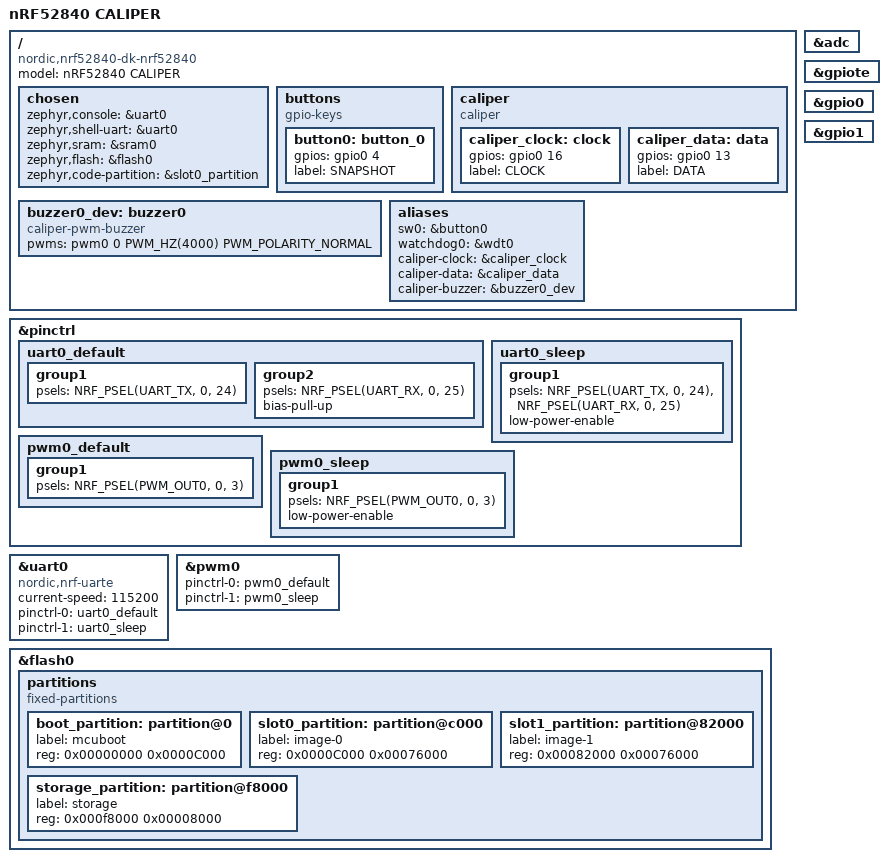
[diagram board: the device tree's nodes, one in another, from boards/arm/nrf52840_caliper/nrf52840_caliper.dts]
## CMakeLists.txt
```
# SPDX-License-Identifier: Apache-2.0

cmake_minimum_required(VERSION 3.20.0)

set_property(GLOBAL APPEND PROPERTY HEX_FILES_TO_MERGE
      ${app_provision_hex})

set(BOARD_ROOT ${CMAKE_CURRENT_SOURCE_DIR})
set(DTS_ROOT_BINDINGS "${CMAKE_CURRENT_SOURCE_DIR}")

# Select the board on the command line, e.g.:
#   west build -b xiao_caliper/nrf52840
# (a BOARD set here would override -b and defeat board qualifiers)

find_package(Zephyr REQUIRED HINTS $ENV{ZEPHYR_BASE})
project(caliper)

include_directories(app PRIVATE inc)

FILE(GLOB app_sources src/*.c)
target_sources(app PRIVATE
  ${app_sources}
  )

# zephyr_compile_options(-save-temps)
```

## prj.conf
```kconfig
#------------------------------------------------
CONFIG_DEBUG=y
CONFIG_GPIO=y
CONFIG_HEAP_MEM_POOL_SIZE=6144
CONFIG_SYSTEM_WORKQUEUE_STACK_SIZE=2048
CONFIG_BUILD_OUTPUT_HEX=y
CONFIG_CBPRINTF_FP_SUPPORT=y
CONFIG_HWINFO=y
CONFIG_HWINFO_NRF=y
CONFIG_REBOOT=y
CONFIG_PWM=y

#
# Why is is option necessary?
#  "No SOURCES given to Zephyr library: xxxxxx"
#
CONFIG_RESET=n

#------------------------------------------------

CONFIG_BT=y
CONFIG_BT_MAX_CONN=2
CONFIG_BT_MAX_PAIRED=2
CONFIG_BT_SMP=y
CONFIG_BT_PERIPHERAL=y
CONFIG_BT_PERIPHERAL_PREF_TIMEOUT=2000
CONFIG_BT_DEVICE_NAME="Caliper Keyboard"
CONFIG_BT_DEVICE_APPEARANCE=961

CONFIG_BT_KEYS_OVERWRITE_OLDEST=y
CONFIG_BT_SMP_ALLOW_UNAUTH_OVERWRITE=y
CONFIG_BT_SMP_SC_PAIR_ONLY=y

CONFIG_BT_SETTINGS=n
CONFIG_BT_LOG_LEVEL_WRN=y

#
# The FIXED_PASSKEY option will generate a warning: ignore it.
# HOG_Keyboard has no method to display a central-side passkey, 
# so HOG_Keyboard uses a FIXED_PASSKEY thereby forcing the 
# central-side into using our fixed passkey.
#
#CONFIG_BT_FIXED_PASSKEY=y

CONFIG_BT_L2CAP_TX_BUF_COUNT=10
CONFIG_BT_BUF_ACL_TX_COUNT=10
CONFIG_BT_BUF_EVT_RX_COUNT=14

#CONFIG_BT_USE_DEBUG_KEYS=y
#CONFIG_BT_STORE_DEBUG_KEYS=y
#CONFIG_BT_LOG_SNIFFER_INFO=y
#CONFIG_BT_SMP_LOG_LEVEL_DBG=y

#------------------------------------------------

CONFIG_ADC_INIT_PRIORITY=50
CONFIG_ADC=y
CONFIG_ADC_ASYNC=y
CONFIG_ADC_LOG_LEVEL_DEFAULT=y
CONFIG_ADC_NRFX_SAADC=y
CONFIG_ADC_SHELL=y

CONFIG_BT_BAS=y

#------------------------------------------------

CONFIG_BT_DIS=y
CONFIG_BT_DIS_PNP=y
CONFIG_BT_DIS_MANUF_NAME_STR="Manufacturer"
CONFIG_BT_DIS_PNP_VID_SRC=2
CONFIG_BT_DIS_PNP_VID=0x1915
CONFIG_BT_DIS_PNP_PID=0xEEEF
CONFIG_BT_DIS_PNP_VER=0x0100

#------------------------------------------------

CONFIG_FLASH=y
CONFIG_FLASH_PAGE_LAYOUT=y
CONFIG_FLASH_MAP=y
CONFIG_NVS=y
CONFIG_SETTINGS=y
CONFIG_MPU_ALLOW_FLASH_WRITE=y

#------------------------------------------------

CONFIG_UART_INTERRUPT_DRIVEN=y
CONFIG_CLOCK_CONTROL_NRF_SHELL=n

CONFIG_FLASH_SHELL=y
CONFIG_FLASH_SHELL_BUFFER_SIZE=0x1000
CONFIG_RING_BUFFER=y

CONFIG_HWINFO_SHELL=y
CONFIG_GETOPT=y
CONFIG_POSIX_C_LIB_EXT=y

CONFIG_SHELL_LOG_LEVEL_WRN=y
CONFIG_SHELL_BACKEND_SERIAL_LOG_LEVEL_WRN=y

CONFIG_SHELL=y
CONFIG_SHELL_BACKENDS=y
CONFIG_SHELL_BACKEND_SERIAL=y
CONFIG_SHELL_BACKEND_SERIAL_INIT_PRIORITY=0
CONFIG_SHELL_PROMPT_UART="uart:~$ "
CONFIG_SHELL_BACKEND_SERIAL_INTERRUPT_DRIVEN=y
CONFIG_SHELL_BACKEND_SERIAL_TX_RING_BUFFER_SIZE=8
CONFIG_SHELL_BACKEND_SERIAL_RX_RING_BUFFER_SIZE=64
CONFIG_SHELL_BACKEND_SERIAL_LOG_MESSAGE_QUEUE_TIMEOUT=100
CONFIG_SHELL_BACKEND_SERIAL_LOG_MESSAGE_QUEUE_SIZE=512
CONFIG_SHELL_STACK_SIZE=2048
CONFIG_SHELL_BACKSPACE_MODE_DELETE=y
CONFIG_SHELL_CMD_BUFF_SIZE=256
CONFIG_SHELL_PRINTF_BUFF_SIZE=30
CONFIG_SHELL_DEFAULT_TERMINAL_WIDTH=80
CONFIG_SHELL_DEFAULT_TERMINAL_HEIGHT=24
CONFIG_SHELL_ARGC_MAX=20
CONFIG_SHELL_TAB=y
CONFIG_SHELL_TAB_AUTOCOMPLETION=y
CONFIG_SHELL_WILDCARD=y
CONFIG_SHELL_ECHO_STATUS=y
CONFIG_SHELL_VT100_COMMANDS=y
CONFIG_SHELL_METAKEYS=y
CONFIG_SHELL_HELP=y
CONFIG_SHELL_HELP_OPT_PARSE=y
CONFIG_SHELL_HELP_ON_WRONG_ARGUMENT_COUNT=y
CONFIG_SHELL_HISTORY=y
CONFIG_SHELL_HISTORY_BUFFER=512
CONFIG_SHELL_STATS=y
CONFIG_SHELL_CMDS=y
CONFIG_SHELL_CMDS_RESIZE=y
CONFIG_SHELL_AUTOSTART=y
CONFIG_SHELL_CMDS_RETURN_VALUE=y
CONFIG_KERNEL_SHELL=y
CONFIG_DEVICE_SHELL=y
CONFIG_DEVMEM_SHELL=y

CONFIG_SHELL_LOG_FORMAT_TIMESTAMP=n
CONFIG_SHELL_LOG_BACKEND=n

#------------------------------------------------

CONFIG_GPIO=y

#------------------------------------------------

CONFIG_WATCHDOG=y
CONFIG_WDT_LOG_LEVEL_DBG=y

#------------------------------------------------

CONFIG_USE_SEGGER_RTT=y
CONFIG_SEGGER_RTT_MAX_NUM_UP_BUFFERS=5
CONFIG_SEGGER_RTT_MAX_NUM_DOWN_BUFFERS=5
CONFIG_SEGGER_RTT_BUFFER_SIZE_UP=2048
CONFIG_SEGGER_RTT_BUFFER_SIZE_DOWN=16
CONFIG_SEGGER_RTT_PRINTF_BUFFER_SIZE=64
CONFIG_SEGGER_RTT_MODE_NO_BLOCK_SKIP=y

CONFIG_LOG=y
CONFIG_LOG_DEFAULT_LEVEL=3
CONFIG_LOG_OVERRIDE_LEVEL=0
CONFIG_LOG_MAX_LEVEL=4
CONFIG_LOG_FUNC_NAME_PREFIX_DBG=y
CONFIG_LOG_PRINTK=y
CONFIG_LOG_MODE_OVERFLOW=y
CONFIG_LOG_PROCESS_TRIGGER_THRESHOLD=30
CONFIG_LOG_PROCESS_THREAD=y
CONFIG_LOG_PROCESS_THREAD_SLEEP_MS=1000
CONFIG_LOG_PROCESS_THREAD_STACK_SIZE=768
CONFIG_LOG_BUFFER_SIZE=2048

CONFIG_LOG_BACKEND_RTT=y
CONFIG_LOG_BACKEND_RTT_MODE_DROP=y
CONFIG_LOG_BACKEND_RTT_BUFFER=0
CONFIG_LOG_BACKEND_SHOW_COLOR=y
CONFIG_LOG_BACKEND_RTT_MESSAGE_SIZE=128

CONFIG_LOG_BACKEND_UART=n
CONFIG_LOG_BACKEND_FORMAT_TIMESTAMP=n
CONFIG_LOG_BACKEND_SHOW_COLOR=n
```

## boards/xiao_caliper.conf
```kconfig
# xiao_caliper: console/shell on the UART header (see xiao_caliper.overlay).

# Do not bring up the USB stack / CDC ACM console the board enables by default.
CONFIG_BOARD_SERIAL_BACKEND_CDC_ACM=n
CONFIG_SERIAL=y
CONFIG_CONSOLE=y
CONFIG_UART_CONSOLE=y

# LOG_INF output: prj.conf only enables the RTT backend, and the shell log
# backend is off.  Send logs through the shell on the UART, at INF level.
# (Do not also enable LOG_BACKEND_UART: it would fight the shell for uart0.)
CONFIG_SHELL_LOG_BACKEND=y
CONFIG_SHELL_BACKEND_SERIAL_LOG_LEVEL_INF=y
```

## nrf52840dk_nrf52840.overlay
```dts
/* 
 *  Copyright (c) 2023 Callender-Consulting
 *
 *  SPDX-License-Identifier: Apache-2.0
 */

#include <zephyr/dt-bindings/pwm/pwm.h>

/*
 *  Add Caliper GPIO pins to DTS config
 */

/ {
    chosen {
        zephyr,console = &uart0;
        zephyr,shell-uart = &uart0;
        zephyr,sram = &sram0;
        zephyr,flash = &flash0;
        zephyr,code-partition = &slot0_partition;
    };

    caliper {
        caliper_data: data {
            gpios = <&gpio0 3 0>;
            label = "DATA";
        };
        compatible = "caliper";
        caliper_clock: clock {
            gpios = <&gpio0 4 0>;
            label = "CLOCK";
        };
    };

    /*
     * CMT-322-65-SMT-TR passive piezo buzzer, driven via PWM on P0.28
     * (see pwm0_default below).  The period cell is a documentary default;
     * the application selects the actual tone frequency at runtime.
     */
    buzzer0_dev: buzzer0 {
        compatible = "caliper-pwm-buzzer";
        pwms = <&pwm0 0 PWM_HZ(4000) PWM_POLARITY_NORMAL>;
    };

    aliases {
        watchdog0 = &wdt0;
        caliper-data   = &caliper_data;
        caliper-clock  = &caliper_clock;
        caliper-buzzer = &buzzer0_dev;
    };
};

&pinctrl {
    uart0_default: uart0_default {
        group1 {
            psels = <NRF_PSEL(UART_TX,  0, 24)>;
        };
        group2 {
            psels = <NRF_PSEL(UART_RX,  0, 25)>;
            bias-pull-up;
        };
    };

    uart0_sleep: uart0_sleep {
        group1 {
            psels = <NRF_PSEL(UART_TX, 0, 24)>,
                    <NRF_PSEL(UART_RX, 0, 25)>;
            low-power-enable;
        };
    };

    pwm0_default: pwm0_default {
        group1 {
            psels = <NRF_PSEL(PWM_OUT0, 0, 28)>;
        };
    };

    pwm0_sleep: pwm0_sleep {
        group1 {
            psels = <NRF_PSEL(PWM_OUT0, 0, 28)>;
            low-power-enable;
        };
    };    
};

&uart0 {
    compatible = "nordic,nrf-uarte";
    status = "okay";
    current-speed = <115200>;
    pinctrl-0 = <&uart0_default>;
    pinctrl-1 = <&uart0_sleep>;
    pinctrl-names = "default", "sleep";
};
```

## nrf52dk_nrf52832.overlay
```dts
/* 
 *  Copyright (c) 2023 Callender-Consulting
 *
 *  SPDX-License-Identifier: Apache-2.0
 */

/*
 *  Add Caliper GPIO pins to DTS config
 */

/ {
    caliper {
        compatible = "caliper";
        caliper_clock: clock {
            gpios = <&gpio0 3 0>;
            label = "CLOCK";
        };
        caliper_data: data {
            gpios = <&gpio0 4 0>;
            label = "DATA";
        };
        caliper_test: test {
            gpios = <&gpio0 28 0>;
            label = "TEST";
        };
    };

    aliases {
        caliper-clock = &caliper_clock;
        caliper-data  = &caliper_data;
        caliper-test  = &caliper_test;
    };
};

#if 0
/delete-node/ &boot_partition;
/delete-node/ &slot0_partition;
/delete-node/ &slot1_partition;
/delete-node/ &scratch_partition;
/delete-node/ &storage_partition;

&flash0 {
    partitions {
        compatible = "fixed-partitions";
        #address-cells = <1>;
        #size-cells = <1>;

        slot0_partition: partition@c000 {
            label = "image-0";
            reg = <0x00000000 0x32000>;
        };
        slot1_partition: partition@3e000 {
            label = "image-1";
            reg = <0x0003E000 0x32000>;
        };
        scratch_partition: partition@70000 {
            label = "image-scratch";
            reg = <0x00070000 0xa000>;
        };
        storage_partition: partition@7a000 {
            label = "storage";
            reg = <0x0007a000 0x00006000>;
        };
    };
};
#endif
```

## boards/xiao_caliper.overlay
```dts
/*
 * xiao_caliper: put the console and shell on uart0 (115200 8N1) instead of
 * the board default (USB CDC ACM).  uart0 is routed to the J1 header:
 *   USART_TX = P1.11 (XIAO D6)   USART_RX = P1.12 (XIAO D7)
 *
 * Pair with boards/xiao_caliper.conf (turns the USB CDC backend off).
 * Delete both files to return to the USB console.
 */
/ {
	chosen {
		zephyr,console = &uart0;
		zephyr,shell-uart = &uart0;
	};
};
```

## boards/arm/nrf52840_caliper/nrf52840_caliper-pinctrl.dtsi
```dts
/*
 * Copyright (c) 2023 Callender Consulting
 * SPDX-License-Identifier: Apache-2.0
 */

&pinctrl {
    uart0_default: uart0_default {
        group1 {
            psels = <NRF_PSEL(UART_TX,  0, 24)>;
            psels = <NRF_PSEL(UART_RX,  0, 25)>;
        };
    };

    uart0_sleep: uart0_sleep {
        group1 {
            psels = <NRF_PSEL(UART_TX, 0, 24)>,
                    <NRF_PSEL(UART_RX, 0, 25)>;
            low-power-enable;
        };
    };   
};
```

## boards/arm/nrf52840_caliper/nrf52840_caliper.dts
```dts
/*
 * Copyright (c) 2023 Callender Consulting
 *
 * SPDX-License-Identifier: Apache-2.0
 */

/dts-v1/;
#include <nordic/nrf52840_qiaa.dtsi>
#include <zephyr/dt-bindings/pwm/pwm.h>

/ {
    model = "nRF52840 CALIPER";
    compatible = "nordic,nrf52840-dk-nrf52840";

    chosen {
        zephyr,console = &uart0;
        zephyr,shell-uart = &uart0;
        zephyr,sram = &sram0;
        zephyr,flash = &flash0;
        zephyr,code-partition = &slot0_partition;
    };

    buttons {
        compatible = "gpio-keys";
        button0: button_0 {
            gpios = <&gpio0 4 (GPIO_PULL_DOWN | GPIO_ACTIVE_HIGH)>;
            label = "SNAPSHOT";
        };
    };

    caliper {
        compatible = "caliper";
        caliper_clock: clock {
            gpios = <&gpio0 16 0>;
            label = "CLOCK";
        };
        caliper_data: data {
            gpios = <&gpio0 13 0>;
            label = "DATA";
        };
    };

    /*
     * CMT-322-65-SMT-TR passive piezo buzzer, driven via PWM on P0.03.
     * Bound to this application's "caliper-pwm-buzzer" binding.
     * The period cell below (PWM_HZ(4000)) is a documentary default; the
     * application selects the actual tone frequency at runtime.
     */
    buzzer0_dev: buzzer0 {
        compatible = "caliper-pwm-buzzer";
        pwms = <&pwm0 0 PWM_HZ(4000) PWM_POLARITY_NORMAL>;
    };

    aliases {
        sw0            = &button0;
        watchdog0      = &wdt0;
        caliper-clock  = &caliper_clock;
        caliper-data   = &caliper_data;
        caliper-buzzer = &buzzer0_dev;
    };
};

&adc {
    status = "okay";
};

&gpiote {
    status = "okay";
};

&gpio0 {
    status = "okay";
};

&gpio1 {
    status = "okay";
};

&pinctrl {
    uart0_default: uart0_default {
        group1 {
            psels = <NRF_PSEL(UART_TX,  0, 24)>;
        };
        group2 {
            psels = <NRF_PSEL(UART_RX,  0, 25)>;
            bias-pull-up;
        };
    };

    uart0_sleep: uart0_sleep {
        group1 {
            psels = <NRF_PSEL(UART_TX, 0, 24)>,
                    <NRF_PSEL(UART_RX, 0, 25)>;
            low-power-enable;
        };
    };

    pwm0_default: pwm0_default {
        group1 {
            psels = <NRF_PSEL(PWM_OUT0, 0, 3)>;
        };
    };

    pwm0_sleep: pwm0_sleep {
        group1 {
            psels = <NRF_PSEL(PWM_OUT0, 0, 3)>;
            low-power-enable;
        };
    };
};

&uart0 {
    compatible = "nordic,nrf-uarte";
    status = "okay";
    current-speed = <115200>;
    pinctrl-0 = <&uart0_default>;
    pinctrl-1 = <&uart0_sleep>;
    pinctrl-names = "default", "sleep";
};

&pwm0 {
    status = "okay";
    pinctrl-0 = <&pwm0_default>;
    pinctrl-1 = <&pwm0_sleep>;
    pinctrl-names = "default", "sleep";
};

&flash0 {

    partitions {
        compatible = "fixed-partitions";
        #address-cells = <1>;
        #size-cells = <1>;

        boot_partition: partition@0 {
            label = "mcuboot";
            reg = <0x00000000 0x0000C000>;
        };
        slot0_partition: partition@c000 {
            label = "image-0";
            reg = <0x0000C000 0x00076000>;
        };
        slot1_partition: partition@82000 {
            label = "image-1";
            reg = <0x00082000 0x00076000>;
        };

        /*
         * The flash starting at 0x000f8000 and ending at
         * 0x000fffff is reserved for use by the application.
         */

        /*
         * Storage partition will be used by FCB/LittleFS/NVS
         * if enabled.
         */
        storage_partition: partition@f8000 {
            label = "storage";
            reg = <0x000f8000 0x00008000>;
        };
    };
};

#if 0
zephyr_udc0: &usbd {
    compatible = "nordic,nrf-usbd";
    status = "okay";
};
#endif
```

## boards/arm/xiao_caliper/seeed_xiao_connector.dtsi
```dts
/*
 * Copyright (c) 2022 Peter Johanson
 * Copyright (c) 2022 Marcin Niestroj
 * Copyright (c) 2026 Robin Callender
 *
 * SPDX-License-Identifier: Apache-2.0
 */

/ {
	xiao_d: connector {
		compatible = "seeed,xiao-gpio";
		#gpio-cells = <2>;
		gpio-map-mask = <0xffffffff 0xffffffc0>;
		gpio-map-pass-thru = <0 0x3f>;
		gpio-map = <0 0 &gpio0 2 0>,		/* D0 */
			   <1 0 &gpio0 3 0>,		/* D1 */
			   <2 0 &gpio0 28 0>,		/* D2 */
			   <3 0 &gpio0 29 0>,		/* D3 */
			   <4 0 &gpio0 4 0>,		/* D4 */
			   <5 0 &gpio0 5 0>,		/* D5 */
			   <6 0 &gpio1 11 0>,		/* D6 */
			   <7 0 &gpio1 12 0>,		/* D7 */
			   <8 0 &gpio1 13 0>,		/* D8 */
			   <9 0 &gpio1 14 0>,		/* D9 */
			   <10 0 &gpio1 15 0>;		/* D10 */
	};
};

xiao_spi: &spi2 {};

xiao_i2c: &i2c1 {};

xiao_serial: &uart0 {};

xiao_adc: &adc {};
```

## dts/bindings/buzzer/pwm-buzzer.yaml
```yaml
# Copyright (c) 2023  Callender_Consulting
# SPDX-License-Identifier: Apache-2.0

description: PWM Buzzer parent node

compatible: "pwm-buzzer"

child-binding:
  description: PWM Buzzer child node
  properties:
    pwms:
      required: true
      type: phandle-array

    label:
      type: string
      description: |
        Human readable string describing the Buzzer. 
```

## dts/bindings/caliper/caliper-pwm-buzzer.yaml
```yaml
# Copyright (c) 2026 Callender-Consulting
# SPDX-License-Identifier: Apache-2.0

description: |
  Passive piezo buzzer driven by one PWM channel (e.g. through a FET).
  The application chooses tone frequency and duty cycle at run time; the
  period cell in 'pwms' is only a documentary default.

compatible: "caliper-pwm-buzzer"

include: base.yaml

properties:
  pwms:
    type: phandle-array
    required: true
```

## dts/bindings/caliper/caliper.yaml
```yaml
description: Digital Caliper

compatible: "caliper"

child-binding:
    description: caliper child node
    properties:
        gpios:
            type: phandle-array
            required: true
        label:
            required: true
            type: string
        debounce:
            required: false
            type: int
```

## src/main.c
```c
/* 
 *  main.c - Application main entry point 
 */
#include <stdio.h>
#include <stdlib.h>
#include <zephyr/kernel.h>
#include <zephyr/sys/printk.h>
#include <zephyr/drivers/hwinfo.h> 

#include "events.h"
#include "watchdog.h"
#include "shell.h"
#include "battery.h"
#include "app_uicr.h"
#include "ble_base.h"
#include "ble_alt.h"
#include "framer.h"
#include "buzzer.h"

#include <zephyr/logging/log.h>
LOG_MODULE_REGISTER(main, 3);

#define STACKSIZE 1024
#define PRIORITY 7

/*---------------------------------------------------------------------------*/
/*                                                                           */
/*---------------------------------------------------------------------------*/

typedef struct {
    uint32_t code;
    char *   text;
} reason_t; 

static reason_t reasons[] = {
    { RESET_PIN,            "Reset Pin"     },  // BIT(0)
    { RESET_SOFTWARE,       "Software"      },  // BIT(1)
    { RESET_BROWNOUT,       "Brown Out"     },  // BIT(2)
    { RESET_POR,            "POR"           },  // BIT(3)
    { RESET_WATCHDOG,       "Watchdog"      },  // BIT(4)
    { RESET_DEBUG,          "Debug"         },  // BIT(5)
    { RESET_SECURITY,       "Security"      },  // BIT(6)
    { RESET_LOW_POWER_WAKE, "Low Pwr Wake"  },  // BIT(7)
    { RESET_CPU_LOCKUP,     "CPU Lockup"    },  // BIT(8)
    { RESET_PARITY,         "Parity"        },  // BIT(9)
    { RESET_PLL,            "PLL"           },  // BIT(10)
    { RESET_CLOCK,          "Clock"         },  // BIT(11)
    { RESET_HARDWARE,       "Hardware"      },  // BIT(12)
    { RESET_USER,           "User"          },  // BIT(13)
    { RESET_TEMPERATURE,    "Temperature"   },  // BIT(14)
};
#define REASONS_COUNT (sizeof(reasons)/sizeof(reason_t))

static bool alt_ble_app = false;

/*---------------------------------------------------------------------------*/
/*                                                                           */
/*---------------------------------------------------------------------------*/
static char * get_reason_text(uint32_t reset_reason)
{
    static char string[48];

    string[0] = 0;

    for(int i=0; i < REASONS_COUNT; i++) {
        if (reset_reason & reasons[i].code) {
            reset_reason &= ~reasons[i].code;
            strcat(string, reasons[i].text);
            if (reset_reason)
                strcat(string, ", ");
        }
    }
    return (char*) &string;
}

/*---------------------------------------------------------------------------*/
/*                                                                           */
/*---------------------------------------------------------------------------*/
bool is_alt_running(void)
{
    return alt_ble_app;
}

/*---------------------------------------------------------------------------*/
/*                                                                           */
/*---------------------------------------------------------------------------*/
void main_thread(void * id, void * unused1, void * unused2)
{
    uint32_t reset_reason = 0;

    hwinfo_get_reset_cause(&reset_reason);
    hwinfo_clear_reset_cause();

    LOG_INF("*** Reset Reason: (0x%02X) %s", 
            reset_reason, get_reason_text(reset_reason));

    app_uicr_init();

    buttons_init();

    if (boot_button_state() == BOOT_OPTIONS_ALTERNATE) {
        LOG_INF("Alternate BLE service starting...");
        alt_ble_app = true;

        ble_alt_init();
    }
    else {
        LOG_INF("Primary BLE service starting...");        
        ble_base_init();
    }

    battery_init();

    framer_init();

    buzzer_init();

    caliper_init();

    events_init();

    caliper_shell_init();

    watchdog_init();   /* watchdog_init never returns */
}


K_THREAD_DEFINE(main_id, STACKSIZE, main_thread,
                NULL, NULL, NULL, PRIORITY, 0, 0);
```

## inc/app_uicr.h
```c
/*
 *   app_uicr.h
 *
 * Copyright (c) 2023, Callender-Consulting LLC
 *
 * SPDX-License-Identifier: Apache-2.0
 */ 
#ifndef __APP_UICR_H
#define __APP_UICR_H

/*---------------------------------------------------------------------------*/
/*                                                                           */
/*---------------------------------------------------------------------------*/

typedef enum{
    INVALID_LINE_END = 0,
    ASCIIZ           = 1,  // ASCII string with zero end
    NEWLINE          = 2,  // ASCII string with \n and zero end
//    HTAB             = 3,  // ASCII Horizontal Tab and zero end
//    VTAB             = 4,  // ASCII Vertical TAB and zero end
} line_end_t;

typedef enum{
    INVALID_STANDARD = 0,
    INCLUDE          = 1,  // include standard unit: mm or inch literal
    EXCLUDE          = 2,  // no standard unit literal
} standard_t;

/*---------------------------------------------------------------------------*/
/*                                                                           */
/*---------------------------------------------------------------------------*/
void       app_uicr_init(void);
line_end_t app_uicr_get_line_end(void);
void       app_uicr_set_line_end(line_end_t line_end);
standard_t app_uicr_get_standard(void);
void       app_uicr_set_standard(standard_t standard);

#endif  /* __APP_UICR_H */
```

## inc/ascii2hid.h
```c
/*
 *  ascii2hid.h
 *
 *  Copyright (c) 2023   Callender-Consulting
 *
 *  SPDX-License-Identifier: Apache-2.0
 */
#ifndef ASCII2HID_H
#define ASCII2HID_H

#include <stdint.h>
#include <stdbool.h>

/*---------------------------------------------------------------------------*/
/*                                                                           */
/*---------------------------------------------------------------------------*/

int ascii_to_hid(uint8_t ascii);
bool needs_shift(uint8_t ascii);

#endif /* ASCII2HID_H */
```

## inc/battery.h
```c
/*
 *   battery.h
 */
#ifndef __BATTERY_H
#define __BATTERY_H

/* Set invalid (uninitialized) percentage value to something very low */
#define BATTERY_LEVEL_INVALID ((uint8_t)5)

/*---------------------------------------------------------------------------*/
/*                                                                           */
/*---------------------------------------------------------------------------*/
int  battery_init(void);
void battery_start(void);
void battery_stop(void);
void battery_ble_events(bool connected);

#endif  /* __BATTERY_H */
```

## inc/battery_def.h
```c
/*
 * Copyright (c) 2019 Nordic Semiconductor ASA
 *
 * SPDX-License-Identifier: LicenseRef-Nordic-5-Clause
 */

const struct {} battery_def_include_once;

#define BATTERY_MEAS_ADC_INPUT              NRF_SAADC_INPUT_VDD  //HDIV5
#define BATTERY_MEAS_ADC_GAIN               ADC_GAIN_1_6
#define BATTERY_MEAS_VOLTAGE_GAIN           6

#define BATTERY_MEAS_POLL_INTERVAL_MS       60000
#define BATTERY_MEAS_MAX_LEVEL              3200
#define BATTERY_MEAS_MIN_LEVEL              2000

#define VOLTAGE_TO_SOC_DELTA                10

/* 
 * Converting measured battery voltage[mV] to State of Charge[%].
 * First element corresponds to BATTERY_MIN_LEVEL.
 * Each element is VOLTAGE_TO_SOC_DELTA higher than previous.
 * Defined separately for every configuration.
 */
static const uint8_t battery_voltage_to_soc[] = 
{
  // 0   1   2   3   4   5   6   7   8   9 
  //======================================== 
     0,  0,  1,  1,  1,  1,  1,  1,  1,  1,  // 00
     1,  1,  1,  1,  1,  1,  1,  1,  1,  2,  // 10
     2,  2,  2,  2,  2,  2,  2,  2,  3,  3,  // 20
     3,  3,  3,  3,  3,  4,  4,  4,  4,  4,  // 30
     4,  5,  5,  5,  6,  6,  7,  7,  8,  8,  // 40
     9,  9, 10, 11, 12, 13, 13, 14, 15, 16,  // 50
    18, 19, 22, 25, 28, 32, 36, 40, 44, 47,  // 60
    51, 53, 56, 58, 60, 62, 64, 66, 67, 69,  // 70
    71, 72, 74, 76, 77, 79, 81, 82, 84, 85,  // 80
    85, 86, 86, 86, 87, 88, 88, 89, 90, 91,  // 90
    91, 92, 93, 94, 95, 96, 97, 98, 99, 100, // 100
    100
};
```

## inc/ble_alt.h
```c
/*
 *  ble_alt.h
 */
#ifndef __BLE_ALT_H__
#define __BLE_ALT_H__

#include <stdbool.h>

/*---------------------------------------------------------------------------*/
/*                                                                           */
/*---------------------------------------------------------------------------*/
#define ALTERNATE_BT_DEVICE_NAME "Caliper Shell"
#define ALTERNATE_BT_NUS_AUTHEN 0

/*---------------------------------------------------------------------------*/
/*                                                                           */
/*---------------------------------------------------------------------------*/
int ble_alt_init(void);

#endif  // __BLE_ALT_H__
```

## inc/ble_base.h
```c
/*
 *  ble_base.h
 */
#ifndef __BLE_BASE_H__
#define __BLE_BASE_H__

#include <stdbool.h>

/*---------------------------------------------------------------------------*/
/*                                                                           */
/*---------------------------------------------------------------------------*/
typedef void (*ble_connected_callback_t)(bool connected);

void ble_register_connect_handler(ble_connected_callback_t callback);
void ble_unregister_notify_handler(void);

/*---------------------------------------------------------------------------*/
/*                                                                           */
/*---------------------------------------------------------------------------*/
int ble_base_init(void);
bool is_bt_connected(void);

#endif  // __BLE_BASE_H__
```

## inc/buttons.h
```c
/*
 *   buttons.h
 */
#ifndef __BUTTONS_H
#define __BUTTONS_H

/*---------------------------------------------------------------------------*/
/*                                                                           */
/*---------------------------------------------------------------------------*/

 #define NO_PRESS   (-1)
 #define INVALID_ID (-1)

 typedef enum {
     BTN1_ID  = 1,
 //    BTN2_ID  = 2,
 //    BTN3_ID  = 3,
 //    BTN4_ID  = 4,
 } buttons_id_t;

typedef enum {
	BOOT_OPTIONS_NORMAL     = 0,
	BOOT_OPTIONS_ALTERNATE  = 1,
} boot_options_t;

typedef void (*buttons_notify_t)(buttons_id_t id);

/*---------------------------------------------------------------------------*/
/*                                                                           */
/*---------------------------------------------------------------------------*/
void buttons_init(void);
void buttons_register_notify_handler(buttons_notify_t notify);
void buttons_unregister_notify_handler(void);
void buttons_remote_button(void);
boot_options_t boot_button_state(void);

#endif  /* __BUTTONS_H */
```

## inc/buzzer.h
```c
/*
 *  buzzer.h  -- buzzer driver
 *
 *  Copyright (c) 2023   Callender-Consulting
 *
 *  SPDX-License-Identifier: Apache-2.0
 */
#ifndef __BUZZER_H__
#define __BUZZER_H__

#include <zephyr/kernel.h>

typedef enum {
    BUZZER_PLAY_DONE = 0,
    BUZZER_PLAY_TONE,
    BUZZER_PLAY_QUIET,
} buzzer_play_action_t;

typedef struct {
    buzzer_play_action_t  action;    // see enum above
    int                   duration;  // in milliseconds
} buzzer_play_t;

/* Duratiion is in milliseconds */

void     buzzer_init(void);
uint32_t buzzer_play(buzzer_play_t * playlist);

#endif /* __BUZZER_H__ */
```

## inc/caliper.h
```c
/*
 *   caliper.h
 */
#ifndef __CALIPER_H
#define __CALIPER_H

/*---------------------------------------------------------------------------*/
/* Caliper Standards values                                                  */
/*---------------------------------------------------------------------------*/

#define CALIPER_STANDARD_INCH      0x00
#define CALIPER_STANDARD_MM        0x01

/*---------------------------------------------------------------------------*/
/*                                                                           */
/*---------------------------------------------------------------------------*/
void caliper_init(void);
int  caliper_read_value(short * value, int * standard);

#endif  /* __CALIPER_H */
```

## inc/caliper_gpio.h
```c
/*
 * Copyright (c) 2023 Callender-Consulting
 *
 * SPDX-License-Identifier: Apache-2.0
 *
 *   caliper_gpio.h
 */
#ifndef __CALIPER_GPIO_H
#define __CALIPER_GPIO_H

#include <zephyr/devicetree.h>

/*---------------------------------------------------------------------------*/
/*  Pins related to caliper.  The board (or an overlay) provides the nodes   */
/*  and these aliases:  caliper-clock, caliper-data, caliper-buzzer.         */
/*  Optional:           caliper-debug  (logic-analyzer test point).          */
/*---------------------------------------------------------------------------*/

#define CLOCK_NODE      DT_ALIAS(caliper_clock)
#define CLOCK           DT_GPIO_PIN(CLOCK_NODE, gpios)
#define CLOCK_LABEL     DT_PROP(CLOCK_NODE, label)

#define DATA_NODE       DT_ALIAS(caliper_data)
#define DATA            DT_GPIO_PIN(DATA_NODE, gpios)
#define DATA_LABEL      DT_PROP(DATA_NODE, label)

#define DEBUG_NODE      DT_ALIAS(caliper_debug)

/* Passive piezo buzzer, driven by a PWM channel ("caliper-pwm-buzzer"). */
#define BUZZER_NODE     DT_ALIAS(caliper_buzzer)

#endif  /* __CALIPER_GPIO_H */
```

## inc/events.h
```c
/*
 *  events.h
 *
 *  Copyright (c) 2023   Callender-Consulting
 *
 *  SPDX-License-Identifier: Apache-2.0
 */
#ifndef EVENTS_H
#define EVENTS_H

#include <stdio.h>
#include <stdint.h>
#include <stdbool.h>

#include "keyboard.h"
#include "buttons.h"
#include "framer.h"
#include "caliper.h"
#include "ble_base.h"

/*---------------------------------------------------------------------------*/
/*                                                                           */
/*---------------------------------------------------------------------------*/
void events_init(void);

#endif /* EVENTS_H */
```

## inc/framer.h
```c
/*
 *   framer.h
 */
#ifndef __FRAMER_H
#define __FRAMER_H

/*---------------------------------------------------------------------------*/
/*                                                                           */
/*---------------------------------------------------------------------------*/

#define CALIPER_POWER_OFF       false
#define CALIPER_POWER_ON        true

/*---------------------------------------------------------------------------*/
/*                                                                           */
/*---------------------------------------------------------------------------*/
void framer_init(void);
void framer_find_interframe_gap(void);
bool is_caliper_on(void);

/*---------------------------------------------------------------------------*/
/* Used with logic analyzer for debugging purposes.                          */
/*---------------------------------------------------------------------------*/

//#define logic_analyzer_testing 1

#if logic_analyzer_testing
void framerPulseDebug(void);
#endif

#endif  /* __FRAMER_H */
```
